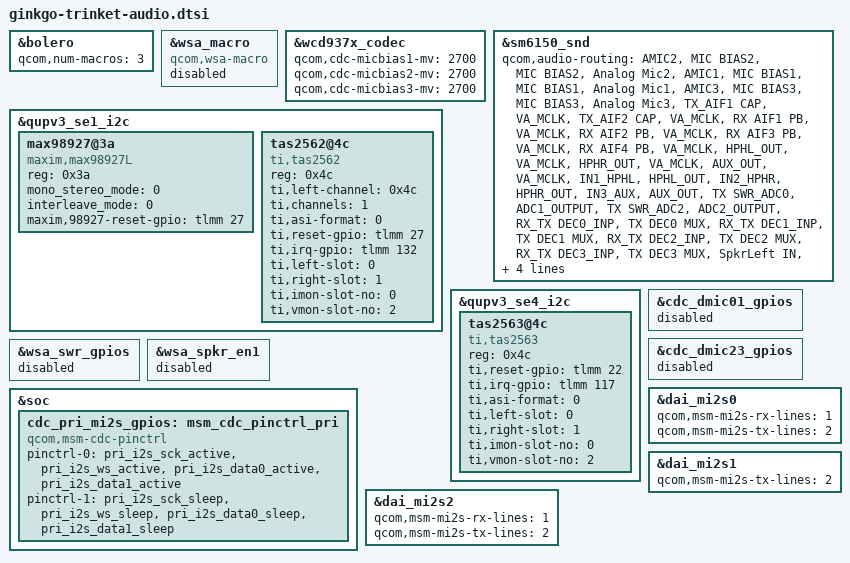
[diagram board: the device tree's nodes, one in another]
#include "../qcom-base/trinket-audio-overlay.dtsi"

&bolero {
    qcom,num-macros = <3>;
};

&wsa_macro {
    compatible = "qcom,wsa-macro";
    status = "disabled";
};

&wcd937x_codec{
    qcom,cdc-micbias1-mv = <2700>;
	qcom,cdc-micbias2-mv = <2700>;
	qcom,cdc-micbias3-mv = <2700>;
};

&sm6150_snd{
    qcom,audio-routing =
		"AMIC2", "MIC BIAS2",
		"MIC BIAS2", "Analog Mic2",
		"AMIC1", "MIC BIAS1",
		"MIC BIAS1", "Analog Mic1",
		"AMIC3", "MIC BIAS3",
		"MIC BIAS3", "Analog Mic3",
		"TX_AIF1 CAP", "VA_MCLK",
		"TX_AIF2 CAP", "VA_MCLK",
		"RX AIF1 PB", "VA_MCLK",
		"RX AIF2 PB", "VA_MCLK",
		"RX AIF3 PB", "VA_MCLK",
		"RX AIF4 PB", "VA_MCLK",
		"HPHL_OUT", "VA_MCLK",
		"HPHR_OUT", "VA_MCLK",
		"AUX_OUT", "VA_MCLK",
		"IN1_HPHL", "HPHL_OUT",
		"IN2_HPHR", "HPHR_OUT",
		"IN3_AUX", "AUX_OUT",
		"TX SWR_ADC0", "ADC1_OUTPUT",
		"TX SWR_ADC2", "ADC2_OUTPUT",
		"RX_TX DEC0_INP", "TX DEC0 MUX",
		"RX_TX DEC1_INP", "TX DEC1 MUX",
		"RX_TX DEC2_INP", "TX DEC2 MUX",
		"RX_TX DEC3_INP", "TX DEC3 MUX",
		"SpkrLeft IN", "WSA_SPK1 OUT",
		"SpkrRight IN", "WSA_SPK2 OUT",
		"WSA_SPK1 OUT", "VA_MCLK",
		"WSA_SPK2 OUT", "VA_MCLK";
	qcom,pri-mi2s-gpios = <&cdc_pri_mi2s_gpios>;
    qcom,wsa-max-devs = <0>;
	/delete-property/ qcom,cdc-dmic01-gpios;
    /delete-property/ qcom,cdc-dmic23-gpios;
    /delete-property/ qcom,wsa-devs;
};

&qupv3_se1_i2c {
	status = "ok";
	max98927@3a {
		compatible = "maxim,max98927L";
		status = "okay";
		reg = <0x3a>;
		mono_stereo_mode = <0>;
		interleave_mode = <0>;
		maxim,98927-reset-gpio = <&tlmm 27 0>;
	};

	tas2562@4c {
		#sound-dai-cells = <0>;
		compatible = "ti,tas2562";
		reg = <0x4c>;
		ti,left-channel = <0x4c>; /*addr*/
		ti,channels = <1>; /* channel number */
		ti,asi-format = <0>; /* 0, i2S; 1, DSP;  */
		ti,reset-gpio = <&tlmm 27 0>;
		ti,irq-gpio = <&tlmm 132 0>;
		ti,left-slot = <0>; /* <left slot number> */
		ti,right-slot = <1>; /* <right slot number> */
		ti,imon-slot-no = <0>; /* <current sense slot number> */
		ti,vmon-slot-no = <2>; /* <current voltage slot number> */
		status = "ok";
	};
};

&qupv3_se4_i2c {
    status = "ok";
    tas2563@4c {
		#sound-dai-cells = <1>;
		compatible = "ti,tas2563";
		reg = <0x4c>;
		ti,reset-gpio = <&tlmm 22 0>;
		ti,irq-gpio = <&tlmm 117 0>;
		ti,asi-format = <0>;
		ti,left-slot = <0>;
		ti,right-slot = <1>;
		ti,imon-slot-no = <0>;
		ti,vmon-slot-no = <2>;
		status = "ok";
	};
};

&cdc_dmic01_gpios {
    status = "disabled";
};

&cdc_dmic23_gpios {
    status = "disabled";
};

&wsa_swr_gpios {
    status = "disabled";
};

&wsa_spkr_en1 {
    status = "disabled";
};

&soc {
    cdc_pri_mi2s_gpios: msm_cdc_pinctrl_pri {
		compatible = "qcom,msm-cdc-pinctrl";
		pinctrl-names = "aud_active", "aud_sleep";
		pinctrl-0 = <&pri_i2s_sck_active &pri_i2s_ws_active
				&pri_i2s_data0_active &pri_i2s_data1_active>;
		pinctrl-1 = <&pri_i2s_sck_sleep &pri_i2s_ws_sleep
				&pri_i2s_data0_sleep &pri_i2s_data1_sleep>;
	};
};

&dai_mi2s0 {
	qcom,msm-mi2s-rx-lines = <1>;
	qcom,msm-mi2s-tx-lines = <2>;
};

&dai_mi2s1 {
	qcom,msm-mi2s-tx-lines = <2>;
};

&dai_mi2s2 {
	qcom,msm-mi2s-rx-lines = <1>;
	qcom,msm-mi2s-tx-lines = <2>;	
};
